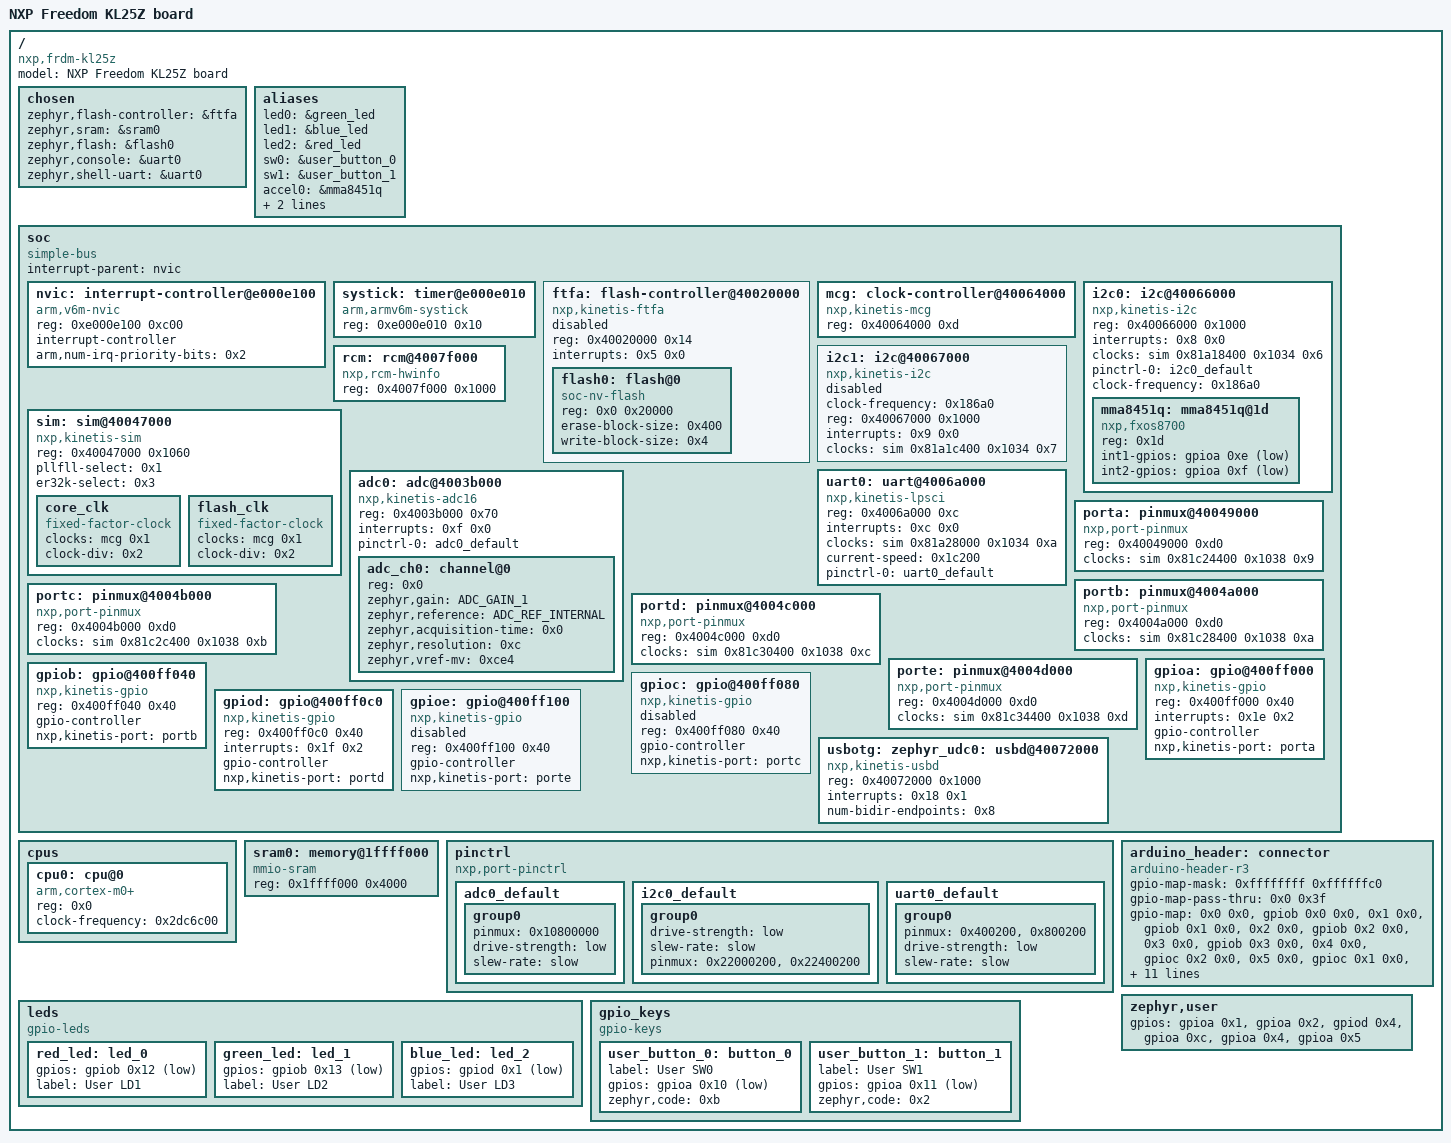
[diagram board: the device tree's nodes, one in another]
/dts-v1/;

/* node '/' defined in zephyr\dts\common\skeleton.dtsi:9 */
/ {
	#address-cells = < 0x1 >;          /* in zephyr\dts\common\skeleton.dtsi:10 */
	#size-cells = < 0x1 >;             /* in zephyr\dts\common\skeleton.dtsi:11 */
	model = "NXP Freedom KL25Z board"; /* in zephyr\boards\nxp\frdm_kl25z\frdm_kl25z.dts:15 */
	compatible = "nxp,frdm-kl25z",
	             "nxp,kl25z",
	             "nxp,mkl25z4";        /* in zephyr\boards\nxp\frdm_kl25z\frdm_kl25z.dts:16 */

	/* node '/chosen' defined in zephyr\dts\common\skeleton.dtsi:13 */
	chosen {
		zephyr,flash-controller = &ftfa; /* in zephyr\dts\arm\nxp\kinetis\nxp_kl25z.dtsi:18 */
		zephyr,sram = &sram0;            /* in zephyr\boards\nxp\frdm_kl25z\frdm_kl25z.dts:28 */
		zephyr,flash = &flash0;          /* in zephyr\boards\nxp\frdm_kl25z\frdm_kl25z.dts:29 */
		zephyr,console = &uart0;         /* in zephyr\boards\nxp\frdm_kl25z\frdm_kl25z.dts:30 */
		zephyr,shell-uart = &uart0;      /* in zephyr\boards\nxp\frdm_kl25z\frdm_kl25z.dts:31 */
	};

	/* node '/aliases' defined in zephyr\dts\common\skeleton.dtsi:15 */
	aliases {
		led0 = &green_led;         /* in zephyr\boards\nxp\frdm_kl25z\frdm_kl25z.dts:19 */
		led1 = &blue_led;          /* in zephyr\boards\nxp\frdm_kl25z\frdm_kl25z.dts:20 */
		led2 = &red_led;           /* in zephyr\boards\nxp\frdm_kl25z\frdm_kl25z.dts:21 */
		sw0 = &user_button_0;      /* in zephyr\boards\nxp\frdm_kl25z\frdm_kl25z.dts:22 */
		sw1 = &user_button_1;      /* in zephyr\boards\nxp\frdm_kl25z\frdm_kl25z.dts:23 */
		accel0 = &mma8451q;        /* in zephyr\boards\nxp\frdm_kl25z\frdm_kl25z.dts:24 */
		my-adc = &adc0;            /* in projects\tracker_solar\boards\frdm_kl25z.overlay:3 */
		my-adc-channel = &adc_ch0; /* in projects\tracker_solar\boards\frdm_kl25z.overlay:4 */
	};

	/* node '/soc' defined in zephyr\dts\arm\armv6-m.dtsi:6 */
	soc {
		#address-cells = < 0x1 >;     /* in zephyr\dts\arm\armv6-m.dtsi:7 */
		#size-cells = < 0x1 >;        /* in zephyr\dts\arm\armv6-m.dtsi:8 */
		compatible = "simple-bus";    /* in zephyr\dts\arm\armv6-m.dtsi:9 */
		interrupt-parent = < &nvic >; /* in zephyr\dts\arm\armv6-m.dtsi:10 */
		ranges;                       /* in zephyr\dts\arm\armv6-m.dtsi:11 */

		/* node '/soc/interrupt-controller@e000e100' defined in zephyr\dts\arm\armv6-m.dtsi:13 */
		nvic: interrupt-controller@e000e100 {
			#address-cells = < 0x1 >;            /* in zephyr\dts\arm\armv6-m.dtsi:14 */
			compatible = "arm,v6m-nvic";         /* in zephyr\dts\arm\armv6-m.dtsi:15 */
			reg = < 0xe000e100 0xc00 >;          /* in zephyr\dts\arm\armv6-m.dtsi:16 */
			interrupt-controller;                /* in zephyr\dts\arm\armv6-m.dtsi:17 */
			#interrupt-cells = < 0x2 >;          /* in zephyr\dts\arm\armv6-m.dtsi:18 */
			arm,num-irq-priority-bits = < 0x2 >; /* in zephyr\dts\arm\nxp\kinetis\nxp_kl25z.dtsi:220 */
			phandle = < 0x1 >;                   /* in zephyr\dts\arm\armv6-m.dtsi:10 */
		};

		/* node '/soc/timer@e000e010' defined in zephyr\dts\arm\armv6-m.dtsi:21 */
		systick: timer@e000e010 {
			compatible = "arm,armv6m-systick"; /* in zephyr\dts\arm\armv6-m.dtsi:22 */
			reg = < 0xe000e010 0x10 >;         /* in zephyr\dts\arm\armv6-m.dtsi:23 */
		};

		/* node '/soc/flash-controller@40020000' defined in zephyr\dts\arm\nxp\kinetis\nxp_kl25z.dtsi:44 */
		ftfa: flash-controller@40020000 {
			compatible = "nxp,kinetis-ftfa"; /* in zephyr\dts\arm\nxp\kinetis\nxp_kl25z.dtsi:45 */
			reg = < 0x40020000 0x14 >;       /* in zephyr\dts\arm\nxp\kinetis\nxp_kl25z.dtsi:46 */
			interrupts = < 0x5 0x0 >;        /* in zephyr\dts\arm\nxp\kinetis\nxp_kl25z.dtsi:47 */
			status = "disabled";             /* in zephyr\dts\arm\nxp\kinetis\nxp_kl25z.dtsi:48 */
			#address-cells = < 0x1 >;        /* in zephyr\dts\arm\nxp\kinetis\nxp_kl25z.dtsi:50 */
			#size-cells = < 0x1 >;           /* in zephyr\dts\arm\nxp\kinetis\nxp_kl25z.dtsi:51 */

			/* node '/soc/flash-controller@40020000/flash@0' defined in zephyr\dts\arm\nxp\kinetis\nxp_kl25z.dtsi:53 */
			flash0: flash@0 {
				compatible = "soc-nv-flash";  /* in zephyr\dts\arm\nxp\kinetis\nxp_kl25z.dtsi:54 */
				reg = < 0x0 0x20000 >;        /* in zephyr\dts\arm\nxp\kinetis\nxp_kl25z.dtsi:55 */
				erase-block-size = < 0x400 >; /* in zephyr\dts\arm\nxp\kinetis\nxp_kl25z.dtsi:56 */
				write-block-size = < 0x4 >;   /* in zephyr\dts\arm\nxp\kinetis\nxp_kl25z.dtsi:57 */
			};
		};

		/* node '/soc/clock-controller@40064000' defined in zephyr\dts\arm\nxp\kinetis\nxp_kl25z.dtsi:61 */
		mcg: clock-controller@40064000 {
			compatible = "nxp,kinetis-mcg"; /* in zephyr\dts\arm\nxp\kinetis\nxp_kl25z.dtsi:62 */
			reg = < 0x40064000 0xd >;       /* in zephyr\dts\arm\nxp\kinetis\nxp_kl25z.dtsi:63 */
			#clock-cells = < 0x1 >;         /* in zephyr\dts\arm\nxp\kinetis\nxp_kl25z.dtsi:64 */
			phandle = < 0x5 >;              /* in zephyr\dts\arm\nxp\kinetis\nxp_kl25z.dtsi:101 */
		};

		/* node '/soc/i2c@40066000' defined in zephyr\dts\arm\nxp\kinetis\nxp_kl25z.dtsi:67 */
		i2c0: i2c@40066000 {
			compatible = "nxp,kinetis-i2c";          /* in zephyr\dts\arm\nxp\kinetis\nxp_kl25z.dtsi:68 */
			#address-cells = < 0x1 >;                /* in zephyr\dts\arm\nxp\kinetis\nxp_kl25z.dtsi:70 */
			#size-cells = < 0x0 >;                   /* in zephyr\dts\arm\nxp\kinetis\nxp_kl25z.dtsi:71 */
			reg = < 0x40066000 0x1000 >;             /* in zephyr\dts\arm\nxp\kinetis\nxp_kl25z.dtsi:72 */
			interrupts = < 0x8 0x0 >;                /* in zephyr\dts\arm\nxp\kinetis\nxp_kl25z.dtsi:73 */
			clocks = < &sim 0x81a18400 0x1034 0x6 >; /* in zephyr\dts\arm\nxp\kinetis\nxp_kl25z.dtsi:74 */
			status = "okay";                         /* in projects\tracker_solar\boards\frdm_kl25z.overlay:32 */
			pinctrl-0 = < &i2c0_default >;           /* in projects\tracker_solar\boards\frdm_kl25z.overlay:33 */
			pinctrl-names = "default";               /* in projects\tracker_solar\boards\frdm_kl25z.overlay:34 */
			clock-frequency = < 0x186a0 >;           /* in projects\tracker_solar\boards\frdm_kl25z.overlay:35 */

			/* node '/soc/i2c@40066000/mma8451q@1d' defined in zephyr\boards\nxp\frdm_kl25z\frdm_kl25z.dts:119 */
			mma8451q: mma8451q@1d {
				compatible = "nxp,fxos8700",
				             "nxp,mma8451q";     /* in zephyr\boards\nxp\frdm_kl25z\frdm_kl25z.dts:120 */
				reg = < 0x1d >;                  /* in zephyr\boards\nxp\frdm_kl25z\frdm_kl25z.dts:121 */
				int1-gpios = < &gpioa 0xe 0x1 >; /* in zephyr\boards\nxp\frdm_kl25z\frdm_kl25z.dts:122 */
				int2-gpios = < &gpioa 0xf 0x1 >; /* in zephyr\boards\nxp\frdm_kl25z\frdm_kl25z.dts:123 */
			};
		};

		/* node '/soc/i2c@40067000' defined in zephyr\dts\arm\nxp\kinetis\nxp_kl25z.dtsi:78 */
		i2c1: i2c@40067000 {
			compatible = "nxp,kinetis-i2c";          /* in zephyr\dts\arm\nxp\kinetis\nxp_kl25z.dtsi:79 */
			clock-frequency = < 0x186a0 >;           /* in zephyr\dts\arm\nxp\kinetis\nxp_kl25z.dtsi:80 */
			#address-cells = < 0x1 >;                /* in zephyr\dts\arm\nxp\kinetis\nxp_kl25z.dtsi:81 */
			#size-cells = < 0x0 >;                   /* in zephyr\dts\arm\nxp\kinetis\nxp_kl25z.dtsi:82 */
			reg = < 0x40067000 0x1000 >;             /* in zephyr\dts\arm\nxp\kinetis\nxp_kl25z.dtsi:83 */
			interrupts = < 0x9 0x0 >;                /* in zephyr\dts\arm\nxp\kinetis\nxp_kl25z.dtsi:84 */
			clocks = < &sim 0x81a1c400 0x1034 0x7 >; /* in zephyr\dts\arm\nxp\kinetis\nxp_kl25z.dtsi:85 */
			status = "disabled";                     /* in zephyr\dts\arm\nxp\kinetis\nxp_kl25z.dtsi:86 */
		};

		/* node '/soc/rcm@4007f000' defined in zephyr\dts\arm\nxp\kinetis\nxp_kl25z.dtsi:89 */
		rcm: rcm@4007f000 {
			compatible = "nxp,rcm-hwinfo"; /* in zephyr\dts\arm\nxp\kinetis\nxp_kl25z.dtsi:90 */
			reg = < 0x4007f000 0x1000 >;   /* in zephyr\dts\arm\nxp\kinetis\nxp_kl25z.dtsi:91 */
		};

		/* node '/soc/sim@40047000' defined in zephyr\dts\arm\nxp\kinetis\nxp_kl25z.dtsi:94 */
		sim: sim@40047000 {
			compatible = "nxp,kinetis-sim",
			             "nxp,sim-uuid";    /* in zephyr\dts\arm\nxp\kinetis\nxp_kl25z.dtsi:95 */
			reg = < 0x40047000 0x1060 >;    /* in zephyr\dts\arm\nxp\kinetis\nxp_kl25z.dtsi:96 */
			#clock-cells = < 0x3 >;         /* in zephyr\dts\arm\nxp\kinetis\nxp_kl25z.dtsi:97 */
			pllfll-select = < 0x1 >;        /* in zephyr\boards\nxp\frdm_kl25z\frdm_kl25z.dts:100 */
			er32k-select = < 0x3 >;         /* in zephyr\boards\nxp\frdm_kl25z\frdm_kl25z.dts:101 */
			phandle = < 0x2 >;              /* in zephyr\dts\arm\nxp\kinetis\nxp_kl25z.dtsi:74 */

			/* node '/soc/sim@40047000/core_clk' defined in zephyr\dts\arm\nxp\kinetis\nxp_kl25z.dtsi:99 */
			core_clk {
				compatible = "fixed-factor-clock"; /* in zephyr\dts\arm\nxp\kinetis\nxp_kl25z.dtsi:100 */
				clocks = < &mcg 0x1 >;             /* in zephyr\dts\arm\nxp\kinetis\nxp_kl25z.dtsi:101 */
				clock-div = < 0x2 >;               /* in zephyr\dts\arm\nxp\kinetis\nxp_kl25z.dtsi:102 */
				#clock-cells = < 0x0 >;            /* in zephyr\dts\arm\nxp\kinetis\nxp_kl25z.dtsi:103 */
			};

			/* node '/soc/sim@40047000/flash_clk' defined in zephyr\dts\arm\nxp\kinetis\nxp_kl25z.dtsi:106 */
			flash_clk {
				compatible = "fixed-factor-clock"; /* in zephyr\dts\arm\nxp\kinetis\nxp_kl25z.dtsi:107 */
				clocks = < &mcg 0x1 >;             /* in zephyr\dts\arm\nxp\kinetis\nxp_kl25z.dtsi:108 */
				clock-div = < 0x2 >;               /* in zephyr\dts\arm\nxp\kinetis\nxp_kl25z.dtsi:109 */
				#clock-cells = < 0x0 >;            /* in zephyr\dts\arm\nxp\kinetis\nxp_kl25z.dtsi:110 */
			};
		};

		/* node '/soc/uart@4006a000' defined in zephyr\dts\arm\nxp\kinetis\nxp_kl25z.dtsi:114 */
		uart0: uart@4006a000 {
			compatible = "nxp,kinetis-lpsci";        /* in zephyr\dts\arm\nxp\kinetis\nxp_kl25z.dtsi:115 */
			reg = < 0x4006a000 0xc >;                /* in zephyr\dts\arm\nxp\kinetis\nxp_kl25z.dtsi:116 */
			interrupts = < 0xc 0x0 >;                /* in zephyr\dts\arm\nxp\kinetis\nxp_kl25z.dtsi:117 */
			clocks = < &sim 0x81a28000 0x1034 0xa >; /* in zephyr\dts\arm\nxp\kinetis\nxp_kl25z.dtsi:118 */
			status = "okay";                         /* in zephyr\boards\nxp\frdm_kl25z\frdm_kl25z.dts:128 */
			current-speed = < 0x1c200 >;             /* in zephyr\boards\nxp\frdm_kl25z\frdm_kl25z.dts:129 */
			pinctrl-0 = < &uart0_default >;          /* in zephyr\boards\nxp\frdm_kl25z\frdm_kl25z.dts:130 */
			pinctrl-names = "default";               /* in zephyr\boards\nxp\frdm_kl25z\frdm_kl25z.dts:131 */
		};

		/* node '/soc/adc@4003b000' defined in zephyr\dts\arm\nxp\kinetis\nxp_kl25z.dtsi:123 */
		adc0: adc@4003b000 {
			compatible = "nxp,kinetis-adc16"; /* in zephyr\dts\arm\nxp\kinetis\nxp_kl25z.dtsi:124 */
			reg = < 0x4003b000 0x70 >;        /* in zephyr\dts\arm\nxp\kinetis\nxp_kl25z.dtsi:125 */
			interrupts = < 0xf 0x0 >;         /* in zephyr\dts\arm\nxp\kinetis\nxp_kl25z.dtsi:126 */
			#io-channel-cells = < 0x1 >;      /* in zephyr\dts\arm\nxp\kinetis\nxp_kl25z.dtsi:128 */
			pinctrl-0 = < &adc0_default >;    /* in zephyr\boards\nxp\frdm_kl25z\frdm_kl25z.dts:110 */
			pinctrl-names = "default";        /* in zephyr\boards\nxp\frdm_kl25z\frdm_kl25z.dts:111 */
			status = "okay";                  /* in projects\tracker_solar\boards\frdm_kl25z.overlay:9 */
			#address-cells = < 0x1 >;         /* in projects\tracker_solar\boards\frdm_kl25z.overlay:10 */
			#size-cells = < 0x0 >;            /* in projects\tracker_solar\boards\frdm_kl25z.overlay:11 */

			/* node '/soc/adc@4003b000/channel@0' defined in projects\tracker_solar\boards\frdm_kl25z.overlay:13 */
			adc_ch0: channel@0 {
				reg = < 0x0 >;                         /* in projects\tracker_solar\boards\frdm_kl25z.overlay:14 */
				zephyr,gain = "ADC_GAIN_1";            /* in projects\tracker_solar\boards\frdm_kl25z.overlay:15 */
				zephyr,reference = "ADC_REF_INTERNAL"; /* in projects\tracker_solar\boards\frdm_kl25z.overlay:16 */
				zephyr,acquisition-time = < 0x0 >;     /* in projects\tracker_solar\boards\frdm_kl25z.overlay:17 */
				zephyr,resolution = < 0xc >;           /* in projects\tracker_solar\boards\frdm_kl25z.overlay:18 */
				zephyr,vref-mv = < 0xce4 >;            /* in projects\tracker_solar\boards\frdm_kl25z.overlay:19 */
			};
		};

		/* node '/soc/pinmux@40049000' defined in zephyr\dts\arm\nxp\kinetis\nxp_kl25z.dtsi:131 */
		porta: pinmux@40049000 {
			compatible = "nxp,port-pinmux";          /* in zephyr\dts\arm\nxp\kinetis\nxp_kl25z.dtsi:132 */
			reg = < 0x40049000 0xd0 >;               /* in zephyr\dts\arm\nxp\kinetis\nxp_kl25z.dtsi:133 */
			clocks = < &sim 0x81c24400 0x1038 0x9 >; /* in zephyr\dts\arm\nxp\kinetis\nxp_kl25z.dtsi:134 */
			phandle = < 0x8 >;                       /* in zephyr\dts\arm\nxp\kinetis\nxp_kl25z.dtsi:168 */
		};

		/* node '/soc/pinmux@4004a000' defined in zephyr\dts\arm\nxp\kinetis\nxp_kl25z.dtsi:137 */
		portb: pinmux@4004a000 {
			compatible = "nxp,port-pinmux";          /* in zephyr\dts\arm\nxp\kinetis\nxp_kl25z.dtsi:138 */
			reg = < 0x4004a000 0xd0 >;               /* in zephyr\dts\arm\nxp\kinetis\nxp_kl25z.dtsi:139 */
			clocks = < &sim 0x81c28400 0x1038 0xa >; /* in zephyr\dts\arm\nxp\kinetis\nxp_kl25z.dtsi:140 */
			phandle = < 0x9 >;                       /* in zephyr\dts\arm\nxp\kinetis\nxp_kl25z.dtsi:177 */
		};

		/* node '/soc/pinmux@4004b000' defined in zephyr\dts\arm\nxp\kinetis\nxp_kl25z.dtsi:143 */
		portc: pinmux@4004b000 {
			compatible = "nxp,port-pinmux";          /* in zephyr\dts\arm\nxp\kinetis\nxp_kl25z.dtsi:144 */
			reg = < 0x4004b000 0xd0 >;               /* in zephyr\dts\arm\nxp\kinetis\nxp_kl25z.dtsi:145 */
			clocks = < &sim 0x81c2c400 0x1038 0xb >; /* in zephyr\dts\arm\nxp\kinetis\nxp_kl25z.dtsi:146 */
			phandle = < 0xa >;                       /* in zephyr\dts\arm\nxp\kinetis\nxp_kl25z.dtsi:186 */
		};

		/* node '/soc/pinmux@4004c000' defined in zephyr\dts\arm\nxp\kinetis\nxp_kl25z.dtsi:149 */
		portd: pinmux@4004c000 {
			compatible = "nxp,port-pinmux";          /* in zephyr\dts\arm\nxp\kinetis\nxp_kl25z.dtsi:150 */
			reg = < 0x4004c000 0xd0 >;               /* in zephyr\dts\arm\nxp\kinetis\nxp_kl25z.dtsi:151 */
			clocks = < &sim 0x81c30400 0x1038 0xc >; /* in zephyr\dts\arm\nxp\kinetis\nxp_kl25z.dtsi:152 */
			phandle = < 0xb >;                       /* in zephyr\dts\arm\nxp\kinetis\nxp_kl25z.dtsi:196 */
		};

		/* node '/soc/pinmux@4004d000' defined in zephyr\dts\arm\nxp\kinetis\nxp_kl25z.dtsi:155 */
		porte: pinmux@4004d000 {
			compatible = "nxp,port-pinmux";          /* in zephyr\dts\arm\nxp\kinetis\nxp_kl25z.dtsi:156 */
			reg = < 0x4004d000 0xd0 >;               /* in zephyr\dts\arm\nxp\kinetis\nxp_kl25z.dtsi:157 */
			clocks = < &sim 0x81c34400 0x1038 0xd >; /* in zephyr\dts\arm\nxp\kinetis\nxp_kl25z.dtsi:158 */
			phandle = < 0xc >;                       /* in zephyr\dts\arm\nxp\kinetis\nxp_kl25z.dtsi:205 */
		};

		/* node '/soc/gpio@400ff000' defined in zephyr\dts\arm\nxp\kinetis\nxp_kl25z.dtsi:161 */
		gpioa: gpio@400ff000 {
			compatible = "nxp,kinetis-gpio"; /* in zephyr\dts\arm\nxp\kinetis\nxp_kl25z.dtsi:162 */
			reg = < 0x400ff000 0x40 >;       /* in zephyr\dts\arm\nxp\kinetis\nxp_kl25z.dtsi:164 */
			interrupts = < 0x1e 0x2 >;       /* in zephyr\dts\arm\nxp\kinetis\nxp_kl25z.dtsi:165 */
			gpio-controller;                 /* in zephyr\dts\arm\nxp\kinetis\nxp_kl25z.dtsi:166 */
			#gpio-cells = < 0x2 >;           /* in zephyr\dts\arm\nxp\kinetis\nxp_kl25z.dtsi:167 */
			nxp,kinetis-port = < &porta >;   /* in zephyr\dts\arm\nxp\kinetis\nxp_kl25z.dtsi:168 */
			status = "okay";                 /* in zephyr\boards\nxp\frdm_kl25z\frdm_kl25z.dts:135 */
			phandle = < 0x4 >;               /* in zephyr\boards\nxp\frdm_kl25z\frdm_kl25z.dts:122 */
		};

		/* node '/soc/gpio@400ff040' defined in zephyr\dts\arm\nxp\kinetis\nxp_kl25z.dtsi:171 */
		gpiob: gpio@400ff040 {
			compatible = "nxp,kinetis-gpio"; /* in zephyr\dts\arm\nxp\kinetis\nxp_kl25z.dtsi:172 */
			reg = < 0x400ff040 0x40 >;       /* in zephyr\dts\arm\nxp\kinetis\nxp_kl25z.dtsi:174 */
			gpio-controller;                 /* in zephyr\dts\arm\nxp\kinetis\nxp_kl25z.dtsi:175 */
			#gpio-cells = < 0x2 >;           /* in zephyr\dts\arm\nxp\kinetis\nxp_kl25z.dtsi:176 */
			nxp,kinetis-port = < &portb >;   /* in zephyr\dts\arm\nxp\kinetis\nxp_kl25z.dtsi:177 */
			status = "okay";                 /* in zephyr\boards\nxp\frdm_kl25z\frdm_kl25z.dts:139 */
			phandle = < 0xd >;               /* in zephyr\boards\nxp\frdm_kl25z\frdm_kl25z.dts:38 */
		};

		/* node '/soc/gpio@400ff080' defined in zephyr\dts\arm\nxp\kinetis\nxp_kl25z.dtsi:180 */
		gpioc: gpio@400ff080 {
			compatible = "nxp,kinetis-gpio"; /* in zephyr\dts\arm\nxp\kinetis\nxp_kl25z.dtsi:181 */
			status = "disabled";             /* in zephyr\dts\arm\nxp\kinetis\nxp_kl25z.dtsi:182 */
			reg = < 0x400ff080 0x40 >;       /* in zephyr\dts\arm\nxp\kinetis\nxp_kl25z.dtsi:183 */
			gpio-controller;                 /* in zephyr\dts\arm\nxp\kinetis\nxp_kl25z.dtsi:184 */
			#gpio-cells = < 0x2 >;           /* in zephyr\dts\arm\nxp\kinetis\nxp_kl25z.dtsi:185 */
			nxp,kinetis-port = < &portc >;   /* in zephyr\dts\arm\nxp\kinetis\nxp_kl25z.dtsi:186 */
			phandle = < 0xf >;               /* in zephyr\boards\nxp\frdm_kl25z\frdm_kl25z.dts:74 */
		};

		/* node '/soc/gpio@400ff0c0' defined in zephyr\dts\arm\nxp\kinetis\nxp_kl25z.dtsi:189 */
		gpiod: gpio@400ff0c0 {
			compatible = "nxp,kinetis-gpio"; /* in zephyr\dts\arm\nxp\kinetis\nxp_kl25z.dtsi:190 */
			reg = < 0x400ff0c0 0x40 >;       /* in zephyr\dts\arm\nxp\kinetis\nxp_kl25z.dtsi:192 */
			interrupts = < 0x1f 0x2 >;       /* in zephyr\dts\arm\nxp\kinetis\nxp_kl25z.dtsi:193 */
			gpio-controller;                 /* in zephyr\dts\arm\nxp\kinetis\nxp_kl25z.dtsi:194 */
			#gpio-cells = < 0x2 >;           /* in zephyr\dts\arm\nxp\kinetis\nxp_kl25z.dtsi:195 */
			nxp,kinetis-port = < &portd >;   /* in zephyr\dts\arm\nxp\kinetis\nxp_kl25z.dtsi:196 */
			status = "okay";                 /* in zephyr\boards\nxp\frdm_kl25z\frdm_kl25z.dts:143 */
			phandle = < 0xe >;               /* in zephyr\boards\nxp\frdm_kl25z\frdm_kl25z.dts:48 */
		};

		/* node '/soc/gpio@400ff100' defined in zephyr\dts\arm\nxp\kinetis\nxp_kl25z.dtsi:199 */
		gpioe: gpio@400ff100 {
			compatible = "nxp,kinetis-gpio"; /* in zephyr\dts\arm\nxp\kinetis\nxp_kl25z.dtsi:200 */
			status = "disabled";             /* in zephyr\dts\arm\nxp\kinetis\nxp_kl25z.dtsi:201 */
			reg = < 0x400ff100 0x40 >;       /* in zephyr\dts\arm\nxp\kinetis\nxp_kl25z.dtsi:202 */
			gpio-controller;                 /* in zephyr\dts\arm\nxp\kinetis\nxp_kl25z.dtsi:203 */
			#gpio-cells = < 0x2 >;           /* in zephyr\dts\arm\nxp\kinetis\nxp_kl25z.dtsi:204 */
			nxp,kinetis-port = < &porte >;   /* in zephyr\dts\arm\nxp\kinetis\nxp_kl25z.dtsi:205 */
			phandle = < 0x10 >;              /* in zephyr\boards\nxp\frdm_kl25z\frdm_kl25z.dts:74 */
		};

		/* node '/soc/usbd@40072000' defined in zephyr\dts\arm\nxp\kinetis\nxp_kl25z.dtsi:208 */
		usbotg: zephyr_udc0: usbd@40072000 {
			reg = < 0x40072000 0x1000 >;     /* in zephyr\dts\arm\nxp\kinetis\nxp_kl25z.dtsi:210 */
			interrupts = < 0x18 0x1 >;       /* in zephyr\dts\arm\nxp\kinetis\nxp_kl25z.dtsi:211 */
			interrupt-names = "usb_otg";     /* in zephyr\dts\arm\nxp\kinetis\nxp_kl25z.dtsi:212 */
			compatible = "nxp,kinetis-usbd"; /* in zephyr\boards\nxp\frdm_kl25z\frdm_kl25z.dts:147 */
			status = "okay";                 /* in zephyr\boards\nxp\frdm_kl25z\frdm_kl25z.dts:148 */
			num-bidir-endpoints = < 0x8 >;   /* in zephyr\boards\nxp\frdm_kl25z\frdm_kl25z.dts:149 */
		};
	};

	/* node '/cpus' defined in zephyr\dts\arm\nxp\kinetis\nxp_kl25z.dtsi:21 */
	cpus {
		#address-cells = < 0x1 >; /* in zephyr\dts\arm\nxp\kinetis\nxp_kl25z.dtsi:22 */
		#size-cells = < 0x0 >;    /* in zephyr\dts\arm\nxp\kinetis\nxp_kl25z.dtsi:23 */

		/* node '/cpus/cpu@0' defined in zephyr\dts\arm\nxp\kinetis\nxp_kl25z.dtsi:25 */
		cpu0: cpu@0 {
			device_type = "cpu";             /* in zephyr\dts\arm\nxp\kinetis\nxp_kl25z.dtsi:26 */
			compatible = "arm,cortex-m0+";   /* in zephyr\dts\arm\nxp\kinetis\nxp_kl25z.dtsi:27 */
			reg = < 0x0 >;                   /* in zephyr\dts\arm\nxp\kinetis\nxp_kl25z.dtsi:28 */
			clock-frequency = < 0x2dc6c00 >; /* in zephyr\boards\nxp\frdm_kl25z\frdm_kl25z.dts:105 */
		};
	};

	/* node '/memory@1ffff000' defined in zephyr\dts\arm\nxp\kinetis\nxp_kl25z.dtsi:32 */
	sram0: memory@1ffff000 {
		compatible = "mmio-sram";    /* in zephyr\dts\arm\nxp\kinetis\nxp_kl25z.dtsi:33 */
		reg = < 0x1ffff000 0x4000 >; /* in zephyr\dts\arm\nxp\kinetis\nxp_kl25z.dtsi:34 */
	};

	/* node '/pinctrl' defined in zephyr\dts\arm\nxp\kinetis\nxp_kl25z.dtsi:38 */
	pinctrl: pinctrl {
		compatible = "nxp,port-pinctrl"; /* in zephyr\dts\arm\nxp\kinetis\nxp_kl25z.dtsi:39 */
		status = "okay";                 /* in zephyr\dts\arm\nxp\kinetis\nxp_kl25z.dtsi:40 */

		/* node '/pinctrl/adc0_default' defined in zephyr\boards\nxp\frdm_kl25z\frdm_kl25z-pinctrl.dtsi:12 */
		adc0_default: adc0_default {
			phandle = < 0x7 >; /* in zephyr\boards\nxp\frdm_kl25z\frdm_kl25z.dts:110 */

			/* node '/pinctrl/adc0_default/group0' defined in zephyr\boards\nxp\frdm_kl25z\frdm_kl25z-pinctrl.dtsi:13 */
			group0 {
				pinmux = < 0x10800000 >; /* in zephyr\boards\nxp\frdm_kl25z\frdm_kl25z-pinctrl.dtsi:14 */
				drive-strength = "low";  /* in zephyr\boards\nxp\frdm_kl25z\frdm_kl25z-pinctrl.dtsi:15 */
				slew-rate = "slow";      /* in zephyr\boards\nxp\frdm_kl25z\frdm_kl25z-pinctrl.dtsi:16 */
			};
		};

		/* node '/pinctrl/i2c0_default' defined in zephyr\boards\nxp\frdm_kl25z\frdm_kl25z-pinctrl.dtsi:20 */
		i2c0_default: i2c0_default {
			phandle = < 0x3 >; /* in projects\tracker_solar\boards\frdm_kl25z.overlay:33 */

			/* node '/pinctrl/i2c0_default/group0' defined in zephyr\boards\nxp\frdm_kl25z\frdm_kl25z-pinctrl.dtsi:21 */
			group0 {
				drive-strength = "low";  /* in zephyr\boards\nxp\frdm_kl25z\frdm_kl25z-pinctrl.dtsi:24 */
				slew-rate = "slow";      /* in zephyr\boards\nxp\frdm_kl25z\frdm_kl25z-pinctrl.dtsi:25 */
				pinmux = < 0x22000200 >,
				         < 0x22400200 >; /* in projects\tracker_solar\boards\frdm_kl25z.overlay:26 */
			};
		};

		/* node '/pinctrl/uart0_default' defined in zephyr\boards\nxp\frdm_kl25z\frdm_kl25z-pinctrl.dtsi:29 */
		uart0_default: uart0_default {
			phandle = < 0x6 >; /* in zephyr\boards\nxp\frdm_kl25z\frdm_kl25z.dts:130 */

			/* node '/pinctrl/uart0_default/group0' defined in zephyr\boards\nxp\frdm_kl25z\frdm_kl25z-pinctrl.dtsi:30 */
			group0 {
				pinmux = < 0x400200 >,
				         < 0x800200 >;  /* in zephyr\boards\nxp\frdm_kl25z\frdm_kl25z-pinctrl.dtsi:31 */
				drive-strength = "low"; /* in zephyr\boards\nxp\frdm_kl25z\frdm_kl25z-pinctrl.dtsi:33 */
				slew-rate = "slow";     /* in zephyr\boards\nxp\frdm_kl25z\frdm_kl25z-pinctrl.dtsi:34 */
			};
		};
	};

	/* node '/leds' defined in zephyr\boards\nxp\frdm_kl25z\frdm_kl25z.dts:34 */
	leds {
		compatible = "gpio-leds"; /* in zephyr\boards\nxp\frdm_kl25z\frdm_kl25z.dts:35 */

		/* node '/leds/led_0' defined in zephyr\boards\nxp\frdm_kl25z\frdm_kl25z.dts:37 */
		red_led: led_0 {
			gpios = < &gpiob 0x12 0x1 >; /* in zephyr\boards\nxp\frdm_kl25z\frdm_kl25z.dts:38 */
			label = "User LD1";          /* in zephyr\boards\nxp\frdm_kl25z\frdm_kl25z.dts:39 */
		};

		/* node '/leds/led_1' defined in zephyr\boards\nxp\frdm_kl25z\frdm_kl25z.dts:42 */
		green_led: led_1 {
			gpios = < &gpiob 0x13 0x1 >; /* in zephyr\boards\nxp\frdm_kl25z\frdm_kl25z.dts:43 */
			label = "User LD2";          /* in zephyr\boards\nxp\frdm_kl25z\frdm_kl25z.dts:44 */
		};

		/* node '/leds/led_2' defined in zephyr\boards\nxp\frdm_kl25z\frdm_kl25z.dts:47 */
		blue_led: led_2 {
			gpios = < &gpiod 0x1 0x1 >; /* in zephyr\boards\nxp\frdm_kl25z\frdm_kl25z.dts:48 */
			label = "User LD3";         /* in zephyr\boards\nxp\frdm_kl25z\frdm_kl25z.dts:49 */
		};
	};

	/* node '/gpio_keys' defined in zephyr\boards\nxp\frdm_kl25z\frdm_kl25z.dts:53 */
	gpio_keys {
		compatible = "gpio-keys"; /* in zephyr\boards\nxp\frdm_kl25z\frdm_kl25z.dts:54 */

		/* node '/gpio_keys/button_0' defined in zephyr\boards\nxp\frdm_kl25z\frdm_kl25z.dts:56 */
		user_button_0: button_0 {
			label = "User SW0";          /* in zephyr\boards\nxp\frdm_kl25z\frdm_kl25z.dts:57 */
			gpios = < &gpioa 0x10 0x1 >; /* in zephyr\boards\nxp\frdm_kl25z\frdm_kl25z.dts:58 */
			zephyr,code = < 0xb >;       /* in zephyr\boards\nxp\frdm_kl25z\frdm_kl25z.dts:59 */
		};

		/* node '/gpio_keys/button_1' defined in zephyr\boards\nxp\frdm_kl25z\frdm_kl25z.dts:62 */
		user_button_1: button_1 {
			label = "User SW1";          /* in zephyr\boards\nxp\frdm_kl25z\frdm_kl25z.dts:63 */
			gpios = < &gpioa 0x11 0x1 >; /* in zephyr\boards\nxp\frdm_kl25z\frdm_kl25z.dts:64 */
			zephyr,code = < 0x2 >;       /* in zephyr\boards\nxp\frdm_kl25z\frdm_kl25z.dts:65 */
		};
	};

	/* node '/connector' defined in zephyr\boards\nxp\frdm_kl25z\frdm_kl25z.dts:69 */
	arduino_header: connector {
		compatible = "arduino-header-r3";          /* in zephyr\boards\nxp\frdm_kl25z\frdm_kl25z.dts:70 */
		#gpio-cells = < 0x2 >;                     /* in zephyr\boards\nxp\frdm_kl25z\frdm_kl25z.dts:71 */
		gpio-map-mask = < 0xffffffff 0xffffffc0 >; /* in zephyr\boards\nxp\frdm_kl25z\frdm_kl25z.dts:72 */
		gpio-map-pass-thru = < 0x0 0x3f >;         /* in zephyr\boards\nxp\frdm_kl25z\frdm_kl25z.dts:73 */
		gpio-map = < 0x0 0x0 &gpiob 0x0 0x0 >,
		           < 0x1 0x0 &gpiob 0x1 0x0 >,
		           < 0x2 0x0 &gpiob 0x2 0x0 >,
		           < 0x3 0x0 &gpiob 0x3 0x0 >,
		           < 0x4 0x0 &gpioc 0x2 0x0 >,
		           < 0x5 0x0 &gpioc 0x1 0x0 >,
		           < 0x6 0x0 &gpioa 0x1 0x0 >,
		           < 0x7 0x0 &gpioa 0x2 0x0 >,
		           < 0x8 0x0 &gpiod 0x4 0x0 >,
		           < 0x9 0x0 &gpioa 0xc 0x0 >,
		           < 0xa 0x0 &gpioa 0x4 0x0 >,
		           < 0xb 0x0 &gpioa 0x5 0x0 >,
		           < 0xc 0x0 &gpioc 0x8 0x0 >,
		           < 0xd 0x0 &gpioc 0x9 0x0 >,
		           < 0xe 0x0 &gpioa 0xd 0x0 >,
		           < 0xf 0x0 &gpiod 0x5 0x0 >,
		           < 0x10 0x0 &gpiod 0x0 0x0 >,
		           < 0x11 0x0 &gpiod 0x2 0x0 >,
		           < 0x12 0x0 &gpiod 0x3 0x0 >,
		           < 0x13 0x0 &gpiod 0x1 0x0 >,
		           < 0x14 0x0 &gpioe 0x0 0x0 >,
		           < 0x15 0x0 &gpioe 0x1 0x0 >;    /* in zephyr\boards\nxp\frdm_kl25z\frdm_kl25z.dts:74 */
	};

	/* node '/zephyr,user' defined in projects\tracker_solar\boards\frdm_kl25z.overlay:122 */
	zephyr,user {
		gpios = < &gpioa 0x1 0x0 >,
		        < &gpioa 0x2 0x0 >,
		        < &gpiod 0x4 0x0 >,
		        < &gpioa 0xc 0x0 >,
		        < &gpioa 0x4 0x0 >,
		        < &gpioa 0x5 0x0 >; /* in projects\tracker_solar\boards\frdm_kl25z.overlay:132 */
	};
};
